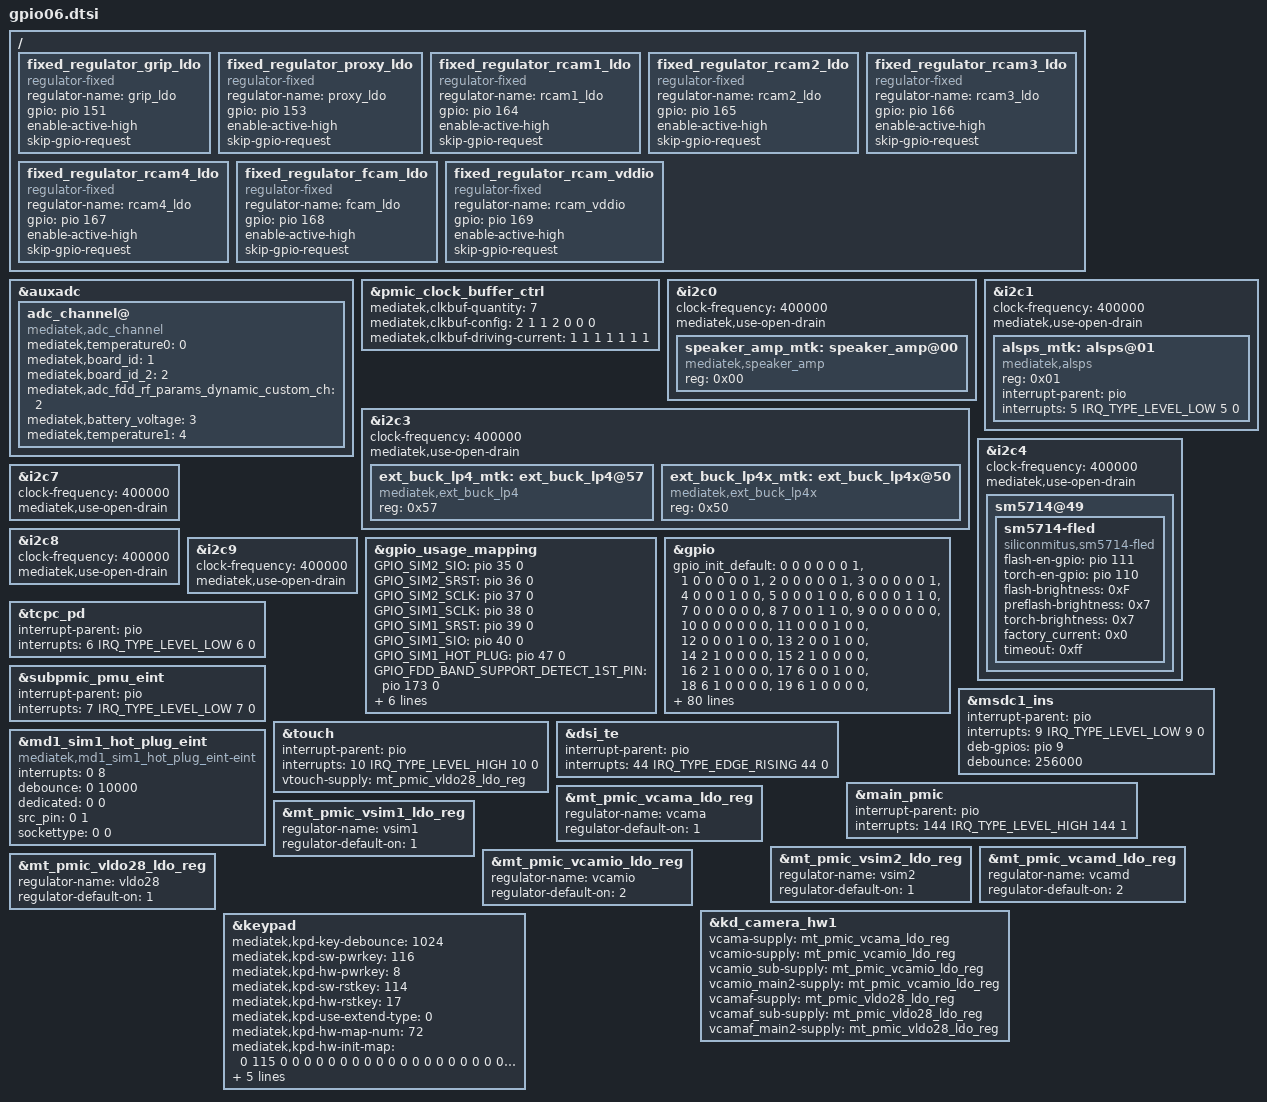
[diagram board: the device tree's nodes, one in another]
// SPDX-License-Identifier: GPL-2.0+
/*
 * Generated by MTK SP DrvGen Version: 3.5.160809 for MT6765.
 * 2020-08-05 19:21:12
 * Do Not Modify The File.
 * Copyright (c) 2019 MediaTek Inc.
 */

/*************************
 * ADC DTSI File
 *************************/

&auxadc {
	adc_channel@ {
		compatible = "mediatek,adc_channel";
		mediatek,temperature0 = <0>;
		mediatek,board_id = <1>;
		mediatek,board_id_2 = <2>;
		mediatek,adc_fdd_rf_params_dynamic_custom_ch = <2>;
		mediatek,battery_voltage = <3>;
		mediatek,temperature1 = <4>;
		status = "okay";
	};
};


/*************************
 * CLK_BUF DTSI File
 *************************/

&pmic_clock_buffer_ctrl {
	mediatek,clkbuf-quantity = <7>;
	mediatek,clkbuf-config = <2 1 1 2 0 0 0>;
	mediatek,clkbuf-driving-current = <1 1 1 1 1 1 1>;
	status = "okay";
};


/*************************
 * I2C DTSI File
 *************************/

&i2c0 {
	#address-cells = <1>;
	#size-cells = <0>;
	clock-frequency = <400000>;
	mediatek,use-open-drain;
	speaker_amp_mtk:speaker_amp@00 {
		compatible = "mediatek,speaker_amp";
		reg = <0x00>;
		status = "okay";
	};

};

&i2c1 {
	#address-cells = <1>;
	#size-cells = <0>;
	clock-frequency = <400000>;
	mediatek,use-open-drain;
	alsps_mtk:alsps@01 {
		compatible = "mediatek,alsps";
		reg = <0x01>;
		status = "okay";
	};

};

&i2c3 {
	#address-cells = <1>;
	#size-cells = <0>;
	clock-frequency = <400000>;
	mediatek,use-open-drain;
	ext_buck_lp4_mtk:ext_buck_lp4@57 {
		compatible = "mediatek,ext_buck_lp4";
		reg = <0x57>;
		status = "okay";
	};

	ext_buck_lp4x_mtk:ext_buck_lp4x@50 {
		compatible = "mediatek,ext_buck_lp4x";
		reg = <0x50>;
		status = "okay";
	};

};

&i2c4 {
	#address-cells = <1>;
	#size-cells = <0>;
	clock-frequency = <400000>;
	mediatek,use-open-drain;
};

&i2c7 {
	#address-cells = <1>;
	#size-cells = <0>;
	clock-frequency = <400000>;
	mediatek,use-open-drain;
};

&i2c8 {
	#address-cells = <1>;
	#size-cells = <0>;
	clock-frequency = <400000>;
	mediatek,use-open-drain;
};

&i2c9 {
	#address-cells = <1>;
	#size-cells = <0>;
	clock-frequency = <400000>;
	mediatek,use-open-drain;
};

&i2c4 {
	sm5714@49 {
		sm5714-fled {
			status = "okay";
			compatible = "siliconmitus,sm5714-fled";
			flash-en-gpio = <&pio 111 0>;
			torch-en-gpio = <&pio 110 0>;

			flash-brightness = <0xF>; //0x0(300mA) ~ 0xF(1500mA) : 50mA Step
			preflash-brightness = <0x7>;
			torch-brightness = <0x7>; //0x0(50mA) ~ 0x7(225mA) : 25mA Step
			factory_current = <0x0>; //0x0(300mA)
			timeout = <0xff>;
		};
	};
};

/*************************
 * GPIO DTSI File
 *************************/

&gpio_usage_mapping {
	GPIO_SIM2_SIO = <&pio 35 0>;
	GPIO_SIM2_SRST = <&pio 36 0>;
	GPIO_SIM2_SCLK = <&pio 37 0>;
	GPIO_SIM1_SCLK = <&pio 38 0>;
	GPIO_SIM1_SRST = <&pio 39 0>;
	GPIO_SIM1_SIO = <&pio 40 0>;
	GPIO_SIM1_HOT_PLUG = <&pio 47 0>;
	GPIO_FDD_BAND_SUPPORT_DETECT_1ST_PIN = <&pio 173 0>;
	GPIO_FDD_BAND_SUPPORT_DETECT_2ND_PIN = <&pio 174 0>;
	GPIO_FDD_BAND_SUPPORT_DETECT_3RD_PIN = <&pio 175 0>;
	GPIO_FDD_BAND_SUPPORT_DETECT_4TH_PIN = <&pio 176 0>;
};

&gpio{
	gpio_init_default = <0 0 0 0 0 0 1>,
		<1 0 0 0 0 0 1>,
		<2 0 0 0 0 0 1>,
		<3 0 0 0 0 0 1>,
		<4 0 0 0 1 0 0>,
		<5 0 0 0 1 0 0>,	/* NC */
		<6 0 0 0 1 1 0>,
		<7 0 0 0 0 0 0>,
		<8 7 0 0 1 1 0>,
		<9 0 0 0 0 0 0>,
		<10 0 0 0 0 0 0>,
		<11 0 0 0 1 0 0>,
		<12 0 0 0 1 0 0>,	/* LCD_ESD_DET */
		<13 2 0 0 1 0 0>,
		<14 2 1 0 0 0 0>,
		<15 2 1 0 0 0 0>,
		<16 2 1 0 0 0 0>,
		<17 6 0 0 1 0 0>,
		<18 6 1 0 0 0 0>,
		<19 6 1 0 0 0 0>,
		<20 6 1 0 0 0 0>,
		<21 5 0 0 1 0 0>,
		<22 5 1 0 0 0 0>,
		<23 5 1 0 0 1 0>,
		<24 5 1 0 0 0 0>,
		<25 1 0 0 1 0 0>,
		<26 1 1 0 0 0 0>,
		<27 1 1 0 0 0 0>,
		<28 1 1 0 0 0 0>,
		<29 1 1 0 0 0 1>,
		<30 1 0 0 1 1 1>,
		<31 1 0 0 1 1 1>,
		<32 1 0 0 1 1 1>,
		<33 1 0 0 1 1 1>,
		<34 1 0 0 1 1 1>,
		<35 1 0 0 1 1 0>,
		<36 1 1 0 0 0 0>,
		<37 1 1 0 0 0 0>,
		<38 1 1 0 0 0 0>,
		<39 1 1 0 0 0 0>,
		<40 1 0 0 1 1 0>,
		<41 0 0 0 0 0 0>,
		<42 0 0 0 0 0 0>,
		<43 0 0 0 0 0 0>,
		<44 0 1 0 0 2 0>,	/* LCD_BL_EN */
		<45 0 1 0 0 2 0>,	/* LCD_RST */
		<46 0 0 0 1 0 0>,
		<47 1 0 0 0 0 0>,
		<48 1 0 0 1 1 1>,
		<49 1 0 0 1 1 1>,
		<50 1 0 0 1 1 1>,
		<51 1 0 0 1 1 1>,
		<52 0 0 0 0 0 0>,
		<53 0 1 0 0 0 0>,
		<54 0 0 0 0 0 0>,
		<55 1 1 0 1 0 0>,
		<56 1 1 0 1 0 0>,
		<57 0 0 0 1 0 0>,
		<58 0 0 0 1 0 0>,
		<59 1 0 0 1 0 0>,
		<60 1 0 0 1 0 0>,
		<61 1 0 0 1 0 0>,
		<62 1 0 0 1 0 0>,
		<63 1 0 0 1 0 0>,
		<64 1 0 0 1 0 0>,
		<65 0 0 0 1 0 0>,
		<66 0 0 0 1 0 0>,
		<67 1 0 0 1 0 0>,
		<68 1 0 0 1 0 0>,
		<69 1 1 0 1 0 0>,
		<70 1 1 0 1 0 0>,
		<71 1 1 0 1 0 0>,
		<72 1 1 0 1 0 0>,
		<73 1 1 0 1 0 0>,
		<74 1 1 0 1 0 0>,
		<75 1 1 0 1 0 0>,
		<76 0 0 0 0 0 0>,
		<77 0 0 0 1 0 0>,
		<78 0 0 0 1 0 0>,
		<79 0 0 0 1 0 0>,
		<80 0 0 0 1 0 0>,
		<81 0 0 0 1 0 0>,	/* NC */
		<82 1 0 0 1 1 1>,
		<83 1 0 0 1 1 1>,
		<84 0 0 0 1 0 0>,	/* NC */
		<85 1 1 0 1 0 0>,
		<86 1 1 0 1 0 0>,
		<87 0 1 0 0 0 0>,
		<88 1 1 0 0 0 0>,
		<89 1 0 0 0 0 0>,
		<90 0 1 0 0 0 0>,
		<91 0 0 0 0 2 0>,	/* LCD_CON_DET */
		<92 0 1 0 0 0 0>,
		<93 1 0 0 1 1 0>,
		<94 1 0 0 1 1 0>,
		<95 1 0 0 1 1 0>,
		<96 1 1 0 0 0 0>,
		<97 0 0 0 1 0 0>,
		<98 0 0 0 1 0 0>,
		<99 1 1 0 0 0 0>,
		<100 1 1 0 0 0 0>,
		<101 0 1 0 0 0 0>,
		<102 0 1 0 0 0 0>,
		<103 1 0 0 1 1 1>,
		<104 1 0 0 1 1 1>,
		<105 1 0 0 0 0 1>,
		<106 1 0 0 0 0 1>,
		<107 0 0 0 1 0 0>,
		<108 1 1 0 0 0 0>,
		<109 0 1 0 0 0 0>,
		<110 0 1 0 0 0 0>,
		<111 0 1 0 0 0 0>,
		<112 0 0 0 1 0 0>,
		<113 1 0 0 1 0 0>,
		<114 1 0 0 1 0 0>,
		<115 1 0 0 1 0 0>,
		<116 1 0 0 1 0 0>,
		<117 1 0 0 1 0 0>,
		<118 1 0 0 1 0 0>,
		<119 1 0 0 1 0 0>,
		<120 1 0 0 1 0 0>,
		<121 1 0 0 1 0 0>,
		<122 1 0 0 1 1 1>,
		<123 1 0 0 1 1 1>,
		<124 1 1 0 0 0 1>,
		<125 1 0 0 1 1 1>,
		<126 1 0 0 1 1 1>,
		<127 1 0 0 1 1 1>,
		<128 1 0 0 1 1 1>,
		<129 1 0 0 1 1 1>,
		<130 1 0 0 1 1 1>,
		<131 1 0 0 1 0 1>,
		<132 1 0 0 1 1 1>,
		<133 1 1 1 0 0 1>,
		<134 1 0 0 1 0 1>,
		<135 1 1 0 0 0 0>,
		<136 1 1 0 0 0 0>,
		<137 1 1 0 0 0 0>,
		<138 1 1 0 0 0 0>,
		<139 1 1 0 0 0 0>,
		<140 1 0 0 1 0 0>,
		<141 1 0 0 1 0 0>,
		<142 1 0 0 1 0 0>,
		<143 1 0 0 1 0 0>,
		<144 1 0 0 1 0 0>,
		<145 1 1 1 0 0 0>,
		<146 1 0 0 1 0 0>,
		<147 1 1 0 0 0 0>,
		<148 1 1 0 0 0 0>,
		<149 1 1 0 0 0 0>,
		<150 0 1 0 0 0 0>,
		<151 0 1 0 0 0 0>,
		<152 0 0 0 1 0 0>,
		<153 0 0 0 1 0 0>,	/* NC */
		<154 0 0 0 1 0 0>,	/* NC */
		<155 7 0 0 1 0 0>,
		<156 7 0 0 1 0 0>,
		<157 7 0 0 1 0 0>,
		<158 7 0 0 1 0 0>,
		<159 0 1 0 0 0 0>,
		<160 0 1 0 0 0 0>,
		<161 1 0 0 1 1 1>,
		<162 1 0 0 1 1 1>,
		<163 0 0 0 1 0 0>,	/* NC */
		<164 0 1 0 0 0 0>,
		<165 0 1 0 0 0 0>,
		<166 0 0 0 1 0 0>,	/* NC */
		<167 0 1 0 0 0 0>,
		<168 0 1 0 0 0 0>,
		<169 0 1 0 0 0 0>,
		<170 0 0 0 0 2 0>,	/* LCD_ID_1 */
		<171 0 0 0 0 2 0>,	/* LCD_ID_2 */
		<172 0 0 0 1 0 0>,
		<173 0 0 0 0 0 0>,
		<174 0 0 0 0 0 0>,
		<175 0 0 0 0 0 0>,
		<176 0 0 0 0 0 0>,
		<177 0 0 0 1 0 0>,	/* NC */
		<178 0 0 0 1 0 0>,	/* NC */
		<179 0 0 0 1 0 0>;
};


/*************************
 * EINT DTSI File
 *************************/

#include <dt-bindings/interrupt-controller/irq.h>
#include <dt-bindings/interrupt-controller/arm-gic.h>

&alsps_mtk {
	interrupt-parent = <&pio>;
	interrupts = <5 IRQ_TYPE_LEVEL_LOW 5 0>;
	status = "okay";
};

&tcpc_pd {
	interrupt-parent = <&pio>;
	interrupts = <6 IRQ_TYPE_LEVEL_LOW 6 0>;
	status = "okay";
};

&subpmic_pmu_eint {
	interrupt-parent = <&pio>;
	interrupts = <7 IRQ_TYPE_LEVEL_LOW 7 0>;
	status = "okay";
};

&msdc1_ins {
	interrupt-parent = <&pio>;
	interrupts = <9 IRQ_TYPE_LEVEL_LOW 9 0>;
	deb-gpios = <&pio 9 0>;
	debounce = <256000>;
	status = "okay";
};

&touch {
	interrupt-parent = <&pio>;
	interrupts = <10 IRQ_TYPE_LEVEL_HIGH 10 0>;
	status = "okay";
};

&dsi_te {
	interrupt-parent = <&pio>;
	interrupts = <44 IRQ_TYPE_EDGE_RISING 44 0>;
	status = "okay";
};

&main_pmic {
	interrupt-parent = <&pio>;
	interrupts = <144 IRQ_TYPE_LEVEL_HIGH 144 1>;
	status = "okay";
};



/*************************
 * MD1_EINT DTSI File
 *************************/

&md1_sim1_hot_plug_eint {
	compatible = "mediatek,md1_sim1_hot_plug_eint-eint";
	interrupts = <0 8>;
	debounce = <0 10000>;
	dedicated = <0 0>;
	src_pin = <0 1>;
	sockettype = <0 0>;
	status = "okay";
};



/*************************
 * PMIC DTSI File
 *************************/

&mt_pmic_vcama_ldo_reg {
	regulator-name = "vcama";
	regulator-default-on = <1>; /* 0:skip, 1: off, 2:on */
	status = "okay";
};
&mt_pmic_vsim1_ldo_reg {
	regulator-name = "vsim1";
	regulator-default-on = <1>; /* 0:skip, 1: off, 2:on */
	status = "okay";
};
&mt_pmic_vsim2_ldo_reg {
	regulator-name = "vsim2";
	regulator-default-on = <1>; /* 0:skip, 1: off, 2:on */
	status = "okay";
};
&mt_pmic_vcamd_ldo_reg {
	regulator-name = "vcamd";
	regulator-default-on = <2>; /* 0:skip, 1: off, 2:on */
	status = "okay";
};
&mt_pmic_vcamio_ldo_reg {
	regulator-name = "vcamio";
	regulator-default-on = <2>; /* 0:skip, 1: off, 2:on */
	status = "okay";
};
&mt_pmic_vldo28_ldo_reg {
	regulator-name = "vldo28";
	regulator-default-on = <1>; /* 0:skip, 1: off, 2:on */
	status = "okay";
};

&kd_camera_hw1 {
	vcama-supply = <&mt_pmic_vcama_ldo_reg>;
	//vcamd_main2-supply = <&mt_pmic_vcamd_ldo_reg>;
	vcamio-supply = <&mt_pmic_vcamio_ldo_reg>;
	vcamio_sub-supply = <&mt_pmic_vcamio_ldo_reg>;
	vcamio_main2-supply = <&mt_pmic_vcamio_ldo_reg>;
	vcamaf-supply = <&mt_pmic_vldo28_ldo_reg>;
	vcamaf_sub-supply = <&mt_pmic_vldo28_ldo_reg>;
	vcamaf_main2-supply = <&mt_pmic_vldo28_ldo_reg>;
	status = "okay";
};

&touch {
	vtouch-supply = <&mt_pmic_vldo28_ldo_reg>;
	status = "okay";
};


/*************************
 * POWER DTSI File
 *************************/
/ {
	fragment@smd {
		target-path = "/";
		__overlay__ {
			fixed_regulator_grip_ldo {
				compatible = "regulator-fixed";
				regulator-name = "grip_ldo";
				gpio = <&pio 151 0>;
				enable-active-high;
				skip-gpio-request;
			};

			fixed_regulator_proxy_ldo {
				compatible = "regulator-fixed";
				regulator-name = "proxy_ldo";
				gpio = <&pio 153 0>;
				enable-active-high;
				skip-gpio-request;
			};

			fixed_regulator_rcam1_ldo {
				compatible = "regulator-fixed";
				regulator-name = "rcam1_ldo";
				gpio = <&pio 164 0>;
				enable-active-high;
				skip-gpio-request;
			};

			fixed_regulator_rcam2_ldo {
				compatible = "regulator-fixed";
				regulator-name = "rcam2_ldo";
				gpio = <&pio 165 0>;
				enable-active-high;
				skip-gpio-request;
			};

			fixed_regulator_rcam3_ldo {
				compatible = "regulator-fixed";
				regulator-name = "rcam3_ldo";
				gpio = <&pio 166 0>;
				enable-active-high;
				skip-gpio-request;
			};

			fixed_regulator_rcam4_ldo {
				compatible = "regulator-fixed";
				regulator-name = "rcam4_ldo";
				gpio = <&pio 167 0>;
				enable-active-high;
				skip-gpio-request;
			};

			fixed_regulator_fcam_ldo {
				compatible = "regulator-fixed";
				regulator-name = "fcam_ldo";
				gpio = <&pio 168 0>;
				enable-active-high;
				skip-gpio-request;
			};

			fixed_regulator_rcam_vddio {
				compatible = "regulator-fixed";
				regulator-name = "rcam_vddio";
				gpio = <&pio 169 0>;
				enable-active-high;
				skip-gpio-request;
			};
		};
	};
};

/*************************
 * KPD DTSI File
 *************************/

&keypad {
	mediatek,kpd-key-debounce = <1024>;
	mediatek,kpd-sw-pwrkey = <116>;
	mediatek,kpd-hw-pwrkey = <8>;
	mediatek,kpd-sw-rstkey  = <114>;
	mediatek,kpd-hw-rstkey = <17>;
	mediatek,kpd-use-extend-type = <0>;
	/*HW Keycode [0~71] -> Linux Keycode*/
	mediatek,kpd-hw-map-num = <72>;
	mediatek,kpd-hw-init-map =
	< 0 115 0 0 0 0 0 0 0 0 0 0 0 0 0 0 0 0 0 0
	0 0 0 0 0 0 0 0 0 0 0 0 0 0 0 0 0 0 0 0
	0 0 0 0 0 0 0 0 0 0 0 0 0 0 0 0 0 0 0 0
	0 0 0 0 0 0 0 0 0 0 0 0 >;
	mediatek,kpd-pwrkey-eint-gpio = <0>;
	mediatek,kpd-pwkey-gpio-din  = <0>;
	mediatek,kpd-hw-dl-key2 = <8>;
	mediatek,kpd-hw-recovery-key = <17>;
	mediatek,kpd-hw-factory-key = <1>;
	status = "okay";
};


